# A31G314 register map
Vendor: ABOV Semiconductor Co., Ltd.; Series: A31G314; File version: 1.0
CPU: CM0PLUS r0p1, little endian, no MPU, no FPU, VTOR, 2 interrupt priority bits
Registers are 32-bit, read-write, reset 0x0 unless marked. A register's access mark holds for its fields unless they carry their own. Offsets are from the block's base; [hi:lo] are bit positions.

## ADPCM
Base 0x40004700
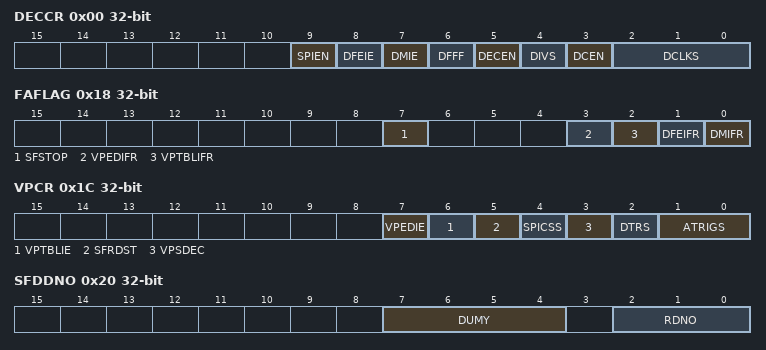
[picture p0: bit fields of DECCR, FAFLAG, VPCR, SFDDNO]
0x00 DECCR — A/D ADPCM Decoder Control Register
  [9] SPIEN — ADPCM Interrupt Enable
  [8] DFEIE — Decoder FIFO Empty Interrupt Enable
  [7] DMIE — Decoder Match Interrupt Enable
  [6] DFFF — Decoder FIFO Full Flag
  [5] DECEN — Decoder Block Enable
  [4] DIVS — Decoder Initial Value Setting
  [3] DCEN — Decoder Counting Enable
  [2:0] DCLKS — Decoder Clock Select (fx/(2^(DCLKS+1)))
0x04 DFIFOR — ADPCM Decoder FIFO Register
  [7:0] DFIFOR — Decoder FIFO Data. The data goes to the decoder FIFO (8-bytes length) if data are written in this register.
0x08 DECDR — ADPCM Decoder Sampling Frequency Data Register
  [7:0] DECDR — Decoder Sampling Frequency Set Register. The sampling time (ts) is 1/(sampling frequency). The voice data get out every ts and interpolation data get out between every the voice data. ex) data1, (data1+data2)/2, data2, (data2+data3)/2, -----.
0x0C DBDLR — ADPCM Decoder Bundle Register
  [7:0] DBDLR — Decoder Bundle Size. This value should be greater than 6. If this value is "00", the bundle size is 256-bytes. This value should be same with encoder's bundle size
0x10 DODRL ro — ADPCM Decoder Result Output Low Register
  [7:0] DODRL rw — Decoder Result Output Data Low Byte. The DODR[15:0] is a binary format.
0x14 DODRH ro — ADPCM Decoder Result Output High Register
  [7:0] DODRH rw — Decoder Result Output Data High Byte
0x18 FAFLAG — ADPCM Interrupt Flag Register
  [7] SFSTOP — Stop the Serial Flash Interface for reading voice data
  [3] VPEDIFR — When voice prompt end interrupt occurs, this bit becomes '1'. The flag is cleared only by writing a '0' to the bit. So, the flag should be cleared by software. Write '1' has no effect.
  [2] VPTBLIFR — When voice prompt table data receive end interrupt occurs, this bit becomes '1'. The flag is cleared only by writing a '0' to the bit. So, the flag should be cleared by software. Write '1' has no effect.
  [1] DFEIFR — When FADPCM decoder FIFO empty interrupt occurs, this bit becomes '1'. The flag is cleared only by writing a '0' to the bit. So, the flag should be cleared by software. Write '1' has no effect.
  [0] DMIFR — When FADPCM decoder match interrupt occurs, this bit becomes '1'. The flag is cleared only by writing a '0' to the bit. So, the flag should be cleared by software. Write '1' has no effect.
0x1C VPCR — Voice Prompt Control Register
  [7] VPEDIE — Voice Prompt End Interrupt Enable
  [6] VPTBLIE — Voice Prompt Table Data Receive End Interrupt Enable
  [5] SFRDST — Serial Flash Data Read Start Signal
  [4] SPICSS — Enable SPI interface for serial flash
  [3] VPSDEC — Voice Prompt Size Register Decrement Enable
  [2] DTRS — Enable Data Transfer from SPI
  [1:0] ATRIGS — Automatically Read Trigger Selection for SPI
0x20 SFDDNO — Serial Flash Dummy and Data Number
  [7:4] DUMY — The number of dummy for serial flash interface. The number of dummy is (n). Where n = 0, 1, 2, ----- and 15.
  [2:0] RDNO — The number of data to read from a serial flash. The number of data to read is (n+1). Where n = 0, 1, 2, ----- and 7. Ex) If n = 7, the voice prompt table data are 8-bytes to read from a serial flash.
0x24 SFCMD — Serial Flash Command Register
  [7:0] SFCMD — Serial Flash Command Data.
0x28 VPADDR1 — Voice Prompt Address Register 1
  [7:0] VPAR — Voice Prompt Address MSB-byte.
0x2C VPADDR2 — Voice Prompt Address Register 2
  [7:0] VPAR — Voice Prompt Address Mid-byte.
0x30 VPADDR3 — Voice Prompt Address Register 3
  [7:0] VPAR — Voice Prompt Address LSB-byte. The VPADDR[23:0] is the start address of a voice prompt or voice prompt table in a serial flash and can access up to 16M-bytes.
0x34 VPSIZE1 — Voice Prompt Size Register 1
  [7:0] VPSZ — Voice Prompt Size MSB-byte.
0x38 VPSIZE2 — Voice Prompt Size Register 2
  [7:0] VPSZ — Voice Prompt Size Mid-byte.
0x3C VPSIZE3 — Voice Prompt Size Register 3
  [7:0] VPSZ — Voice Prompt Size LSB-byte. The VPSIZE[23:0] is the size of a voice prompt to play continuously in a serial flash.
0x40 VPINF1 — Voice Prompt Inform Register 1
  [7:0] VPINF — Voice Prompt Inform High-byte.
0x44 VPINF2 — Voice Prompt Inform Register 2
  [7:0] VPINF — Voice Prompt Inform Low-byte. The VPINF[15:0] is the voice prompt information.
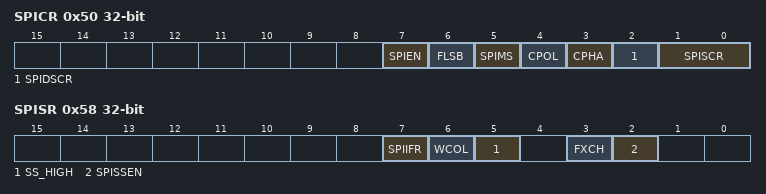
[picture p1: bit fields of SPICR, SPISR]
0x50 SPICR — SPI Control Register
  [7] SPIEN — This bit controls the SPI operation
  [6] FLSB — This bit selects the data transmission sequence
  [5] SPIMS — This bit selects whether Master or Slave mode
  [4] CPOL — This two bits control the serial clock (SCK) mode. Clock polarity (CPOL) bit determine SCK's value at idle mode. Clock phase (CPHA) bit determine if data are sampled on the leading or trailing edge of SCK.
  [3] CPHA — This two bits control the serial clock (SCK) mode. Clock polarity (CPOL) bit determine SCK's value at idle mode. Clock phase (CPHA) bit determine if data are sampled on the leading or trailing edge of SCK.
  [2] SPIDSCR — These three bits select the SCK3 rate of the device configured as a master. When DSCR bit is written one, SCK3 will be doubled in master mode.
  [1:0] SPISCR — These three bits select the SCK3 rate of the device configured as a master. When DSCR bit is written one, SCK3 will be doubled in master mode.
0x54 SPIDR — SPI Data Register
  [7] SPIDR — SPI Data hen it is written a byte to this data register, the SPI 3 will start an operation.
0x58 SPISR — SPI Status Register
  [7] SPIIFR — When SPI Interrupt occurs, this bit becomes '1'. IF SPI interrupt is enable, this bit is auto cleared by INT_ACK signal. And if SPI Interrupt is disable, this bit is cleared when the status register SPISR is read and then access (read/write) the data register SPIDR. Write '1' has no effect.
  [6] WCOL — This bit is set if any data are written to the data register SPIDR during transfer. This bit is cleared when the status register SPISR is read and then access (read/write) the data register SPIDR
  [5] SS_HIGH — When the SS pin is configured as input, if "HIGH" signal comes into the pin, this flag bit will be set.
  [3] FXCH — SPI port function exchange control bit.
  [2] SPISSEN — This bit controls the SS pin operation
